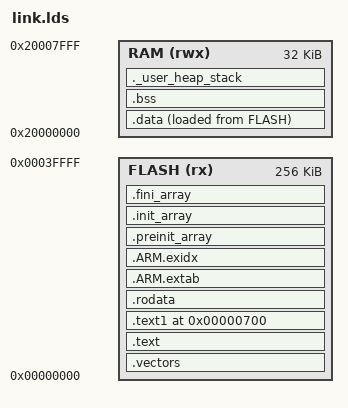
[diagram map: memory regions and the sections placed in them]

/* Highest address of the user mode stack */
_estack = 0x20008000;    /* end of RAM */
/* Generate a link error if heap and stack don't fit into RAM */
_Min_Heap_Size = 0x200;      /* required amount of heap  */
_Min_Stack_Size = 0x200; /* required amount of stack */

/* Use contiguous memory regions for simple. */
MEMORY
{
    FLASH  (rx): ORIGIN = 0x00000000, LENGTH = 256K
    RAM   (rwx): ORIGIN = 0x20000000, LENGTH = 32K
}

ENTRY(Reset_Handler)

SECTIONS
{
    .vectors :
    {
        KEEP(*(.vectors))
    } >FLASH

    .text :
    {
        *(.text)
        *(.text*)
        *(.glue_7)
        *(.glue_7t)
        *(.eh_fream)

        KEEP(*(.init))
        KEEP(*(.fini))
    } >FLASH

    .text1 0x700 :
    {
        *(.ARM.__at_0x600)
    } >FLASH
    
    .rodata :
    {
        . = ALIGN(4);
        *(.rodata)
        *(.rodata*)
        . = ALIGN(4);
    } >FLASH

    .ARM.extab :
    {
        *(.ARM.extab* .gnu.linkonce.armextab.*)
    } >FLASH

    __exidx_start = .;
    .ARM.exidx :
    {
        *(.ARM.exidx* .gnu.linkonce.armexidx.*)
    } >FLASH
    __exidx_end = .;

    .preinit_array :
    {
        /* preinit data */
		PROVIDE_HIDDEN (__preinit_array_start = .);
		KEEP(*(.preinit_array))
		PROVIDE_HIDDEN (__preinit_array_end = .);
    } >FLASH

    .init_array :
    {
        /* init data */
		PROVIDE_HIDDEN (__init_array_start = .);
		KEEP(*(SORT(.init_array.*)))
		KEEP(*(.init_array))
		PROVIDE_HIDDEN (__init_array_end = .);
    } >FLASH

    .fini_array :
    {
        /* finit data */
		PROVIDE_HIDDEN (__fini_array_start = .);
		KEEP(*(SORT(.fini_array.*)))
		KEEP(*(.fini_array))
		PROVIDE_HIDDEN (__fini_array_end = .);
    } >FLASH

    __etext = LOADADDR(.data);
    .data :
    {
        . = ALIGN(4);
        __data_start__ = .;
        *(vtable)
        *(.data)
        *(.data*)
        . = ALIGN(4);
        __data_end__ = .;
    } >RAM AT> FLASH

    .bss :
    {
        . = ALIGN(4);
        __bss_start__ = .;
        *(.bss*)
        *(COMMON)
        . = ALIGN(4);
        __bss_end__ = .;
    } >RAM


    /* User_heap_stack section, used to check that there is enough RAM left */
    ._user_heap_stack :
    {
      . = ALIGN(8);
      PROVIDE ( end = . );
      PROVIDE ( _end = . );
      . = . + _Min_Heap_Size;
      . = . + _Min_Stack_Size;
      . = ALIGN(8);
    } >RAM
    __StackTop = .;
    PROVIDE(_stack = __StackTop);

    ASSERT(__StackTop < _estack, "region RAM overflowed with stack")
}

